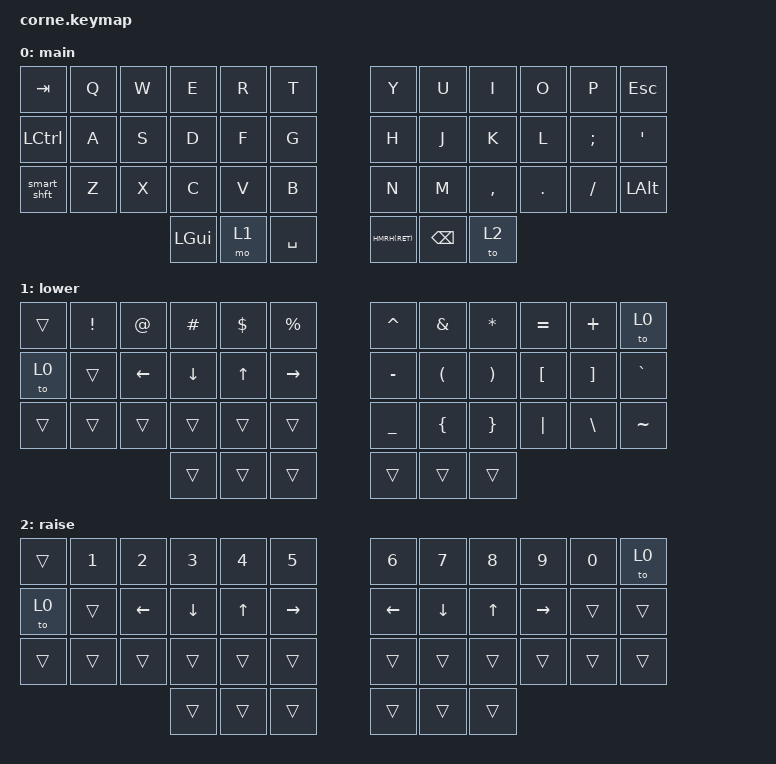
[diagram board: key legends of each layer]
#include <behaviors.dtsi>
#include <dt-bindings/zmk/keys.h>

#include "../zmk-nodefree-config/helper.h"

#define MAIN 0
#define LOWER 1
#define RAISE 2

#define ___ &trans
#define MEH(tap_key) &kp LS(LA(LC(tap_key)))
#define HYPER(tap_key) &kp LS(LA(LC(LG(tap_key))))

#define QUICK_TAP_MS 175

&sk {  // sticky-key config
    release-after-ms = <600>;  // release after 0.6s
    quick-release;             // no double capitalization when rolling keys
};

&sl {  // sticky-layer config
    ignore-modifiers;          // allow chording sticky mods & layers
};

&lt {  // layer-tap config
    flavor = "balanced";
    tapping-term-ms = <200>;
    quick-tap-ms = <QUICK_TAP_MS>;
};

#include "../zmk-nodefree-config/keypos_def/keypos_42keys.h"
#define KEYS_L LT0 LT1 LT2 LT3 LT4 LT5 LM0 LM1 LM2 LM3 LM4 LM5 LB0 LB1 LB2 LB3 LB4 LB5
#define KEYS_R RT0 RT1 RT2 RT3 RT4 RT5 RM0 RM1 RM2 RM3 RM4 RM5 RB0 RB1 RB2 RB3 RB4 RB5
#define THUMBS LH2 LH1 LH0 RH0 RH1 RH2

#define MAKE_HRM(NAME, HOLD, TAP, TRIGGER_POS) \
ZMK_BEHAVIOR(NAME, hold_tap, \
    flavor = "balanced"; \
    tapping-term-ms = <280>; \
    quick-tap-ms = <QUICK_TAP_MS>; \
    global-quick-tap-ms = <150>; \
    bindings = <HOLD>, <TAP>; \
    hold-trigger-key-positions = <TRIGGER_POS>; \
    hold-trigger-on-release; \
)
MAKE_HRM(hml, &kp, &kp, KEYS_R THUMBS)  // left-hand HRMs
MAKE_HRM(hmr, &kp, &kp, KEYS_L THUMBS)  // right-hand HRMs

#define HMLS(tap_key) &hml LSHFT tap_key
#define HMLG(tap_key) &hml LGUI tap_key
#define HMLA(tap_key) &hml LALT tap_key
#define HMLC(tap_key) &hml LCTRL tap_key
#define HMLH(tap_key) &hmr LS(LA(LC(LGUI))) tap_key

#define HMRS(tap_key) &hmr LSHFT tap_key
#define HMRG(tap_key) &hmr LGUI tap_key
#define HMRA(tap_key) &hmr LALT tap_key
#define HMRC(tap_key) &hmr LCTRL tap_key
#define HMRH(tap_key) &hmr LS(LA(LC(LGUI))) tap_key

ZMK_BEHAVIOR(smart_shft, mod_morph,
    bindings = <&sk LSHFT>, <&caps_word>;
    mods = <(MOD_LSFT)>;
)
&caps_word {  // mods deactivate caps-word, requires PR #1441
    /delete-property/ ignore-modifiers;
};

ZMK_LAYER(main,
//╭─────────────┬─────────────┬─────────────┬─────────────┬─────────────┬─────────────╮ ╭─────────────┬─────────────┬─────────────┬─────────────┬────────────┬────────────╮
//├             ┼      Q      ┼      W      ┼      E      ┼      R      ┼      T      ┤ ├      Y      ┼      U      ┼      I      ┼      O      ┼      P     ┼            ┤
    &kp TAB       &kp Q         &kp W         &kp E         &kp R         &kp T           &kp Y         &kp U         &kp I         &kp O         &kp P        &kp ESC
//├─────────────┼─────────────┼─────────────┼─────────────┼─────────────┼─────────────┤ ├─────────────┼─────────────┼─────────────┼─────────────┼────────────┼────────────┤
//├             ┼      A      ┼      S      ┼      D      ┼      F      ┼      G      ┤ ├      H      ┼      J      ┼      K      ┼      L      ┼      ;     ┼      '     ┤
    &kp LCTRL     &kp A         &kp S         &kp D         &kp F         &kp G           &kp H         &kp J         &kp K         &kp L         &kp SEMI     &kp SQT
//├─────────────┼─────────────┼─────────────┼─────────────┼─────────────┼─────────────┤ ├─────────────┼─────────────┼─────────────┼─────────────┼────────────┼────────────┤
//├             ┼      Z      ┼      X      ┼      C      ┼      V      ┼      B      ┤ ├      N      ┼      M      ┼      ,      ┼      .      ┼      /     ┼            ┤
    &smart_shft   &kp Z         &kp X         &kp C         &kp V         &kp B           &kp N         &kp M         &kp COMMA     &kp DOT       &kp FSLH     &kp LALT
//╰─────────────┴─────────────┴─────────────┼─────────────┼─────────────┼─────────────┤ ├─────────────┼─────────────┼─────────────┴─────────────┴────────────┴────────────╯
                                              &kp LGUI      &mo 1         &kp SPACE       HMRH(RET)     &kp BSPC      &to 2
//                                          ╰─────────────┴─────────────┴─────────────╯ ╰─────────────┴─────────────┴─────────────╯                          
)

ZMK_LAYER(lower,
//╭─────────────┬─────────────┬─────────────┬─────────────┬─────────────┬─────────────╮ ╭─────────────┬─────────────┬─────────────┬─────────────┬────────────┬────────────╮
//├             ┼      !      ┼      @      ┼      #      ┼      $      ┼      %      ┤ ├      ^      ┼      &      ┼      *      ┼      =      ┼      +     ┼            ┤
    ___           &kp EXCL      &kp AT        &kp HASH      &kp DLLR      &kp PRCNT       &kp CARET     &kp AMPS      &kp STAR      &kp EQUAL      &kp PLUS    &to 0
//├─────────────┼─────────────┼─────────────┼─────────────┼─────────────┼─────────────┤ ├─────────────┼─────────────┼─────────────┼─────────────┼────────────┼────────────┤
//├             ┼             ┼      <      ┼      ⌄      ┼      ⌃      ┼      >      ┤ ├      -      ┼      (      ┼      )      ┼      [      ┼      ]     ┼      `     ┤
    &to 0         ___           &kp LEFT      &kp DOWN      &kp UP        &kp RIGHT       &kp MINUS     &kp LPAR      &kp RPAR      &kp LBKT      &kp RBKT     &kp GRAVE 
//├─────────────┼─────────────┼─────────────┼─────────────┼─────────────┼─────────────┤ ├─────────────┼─────────────┼─────────────┼─────────────┼────────────┼────────────┤
//├             ┼             ┼             ┼             ┼             ┼             ┤ ├      _      ┼      {      ┼      }      ┼      |      ┼      \     ┼      ~     ┤
    ___           ___           ___           ___           ___           ___             &kp UNDER     &kp LBRC      &kp RBRC      &kp PIPE      &kp BSLH     &kp TILDE   
//╰─────────────┴─────────────┴─────────────┼─────────────┼─────────────┼─────────────┤ ├─────────────┼─────────────┼─────────────┴─────────────┴────────────┴────────────╯
                                              ___           ___           ___             ___           ___           ___   
//                                          ╰─────────────┴─────────────┴─────────────╯ ╰─────────────┴─────────────┴─────────────╯                          
)

ZMK_LAYER(raise,
//╭─────────────┬─────────────┬─────────────┬─────────────┬─────────────┬─────────────╮ ╭─────────────┬─────────────┬─────────────┬─────────────┬────────────┬────────────╮
//├             ┼      1      ┼      2      ┼      3      ┼      4      ┼      5      ┤ ├      6      ┼      7      ┼      8      ┼      9      ┼      0     ┼            ┤
    ___           &kp N1        &kp N2        &kp N3        &kp N4        &kp N5          &kp N6        &kp N7        &kp N8        &kp N9        &kp N0       &to 0
//├─────────────┼─────────────┼─────────────┼─────────────┼─────────────┼─────────────┤ ├─────────────┼─────────────┼─────────────┼─────────────┼────────────┼────────────┤
//├             ┼             ┼      <      ┼      ⌄      ┼      ⌃      ┼      >      ┤ ├      <      ┼      ⌄      ┼      ⌃      ┼      >      ┼            ┼            ┤
    &to 0         ___           &kp LEFT      &kp DOWN      &kp UP        &kp RIGHT       &kp LEFT      &kp DOWN      &kp UP        &kp RIGHT     ___          ___
//├─────────────┼─────────────┼─────────────┼─────────────┼─────────────┼─────────────┤ ├─────────────┼─────────────┼─────────────┼─────────────┼────────────┼────────────┤
//├             ┼             ┼             ┼             ┼             ┼             ┤ ├             ┼             ┼             ┼             ┼            ┼            ┤
    ___           ___           ___           ___           ___           ___             ___           ___           ___           ___           ___          ___
//╰─────────────┴─────────────┴─────────────┼─────────────┼─────────────┼─────────────┤ ├─────────────┼─────────────┼─────────────┴─────────────┴────────────┴────────────╯
                                              ___           ___           ___             ___           ___           ___   
//                                          ╰─────────────┴─────────────┴─────────────╯ ╰─────────────┴─────────────┴─────────────╯                          
)
